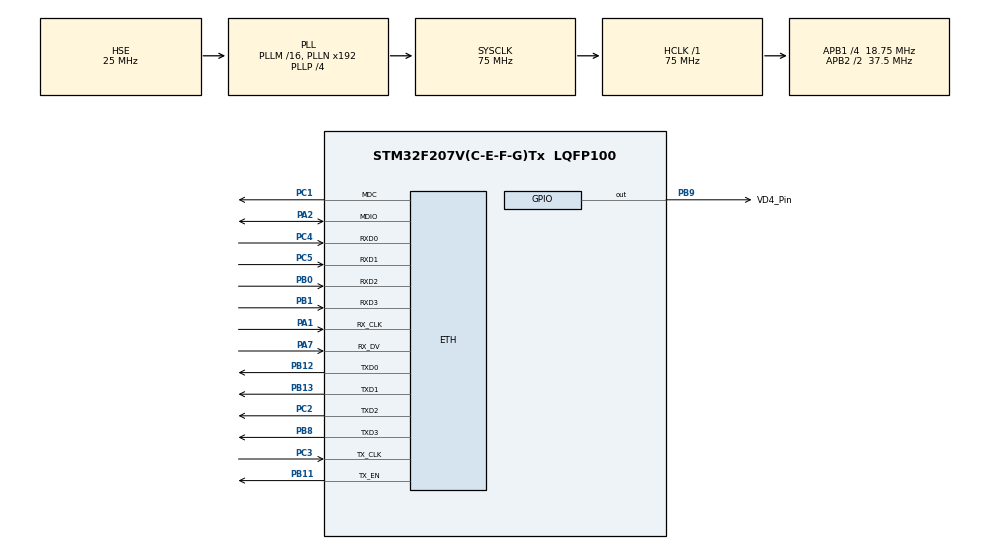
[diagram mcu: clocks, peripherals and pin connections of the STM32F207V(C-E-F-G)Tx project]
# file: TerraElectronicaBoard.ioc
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ETH.MediaInterface=ETH_MEDIA_INTERFACE_MII
ETH.PHY_Name_MII=userPHY
ETH.PHY_User_Name=RTL8201CP
ETH.PhyAddress=31
FREERTOS.Tasks01=defaultTask,0,128,StartDefaultTask,Default,NULL,Dynamic,NULL,NULL
LWIP.IP_ADDRESS=192.168.124.111
LWIP.LWIP_DHCP=0
LWIP.NETMASK_ADDRESS=255.255.255.000
LWIP.Version=v2.0.3_Cube
Mcu.Family=STM32F2
Mcu.Name=STM32F207V(C-E-F-G)Tx
Mcu.Package=LQFP100
NVIC.ETH_IRQn=true\:5\:0\:false\:false\:true\:true\:false\:true
NVIC.PriorityGroup=NVIC_PRIORITYGROUP_4
PA1.Mode=MII Full Duplex Only
PA1.Signal=ETH_RX_CLK
PA2.Mode=MII Full Duplex Only
PA2.Signal=ETH_MDIO
PA7.Mode=MII Full Duplex Only
PA7.Signal=ETH_RX_DV
PB0.Mode=MII Full Duplex Only
PB0.Signal=ETH_RXD2
PB1.Mode=MII Full Duplex Only
PB1.Signal=ETH_RXD3
PB11.Mode=MII Full Duplex Only
PB11.Signal=ETH_TX_EN
PB12.Mode=MII Full Duplex Only
PB12.Signal=ETH_TXD0
PB13.Mode=MII Full Duplex Only
PB13.Signal=ETH_TXD1
PB8.Mode=MII Full Duplex Only
PB8.Signal=ETH_TXD3
PB9.GPIO_Label=VD4_Pin
PB9.Signal=GPIO_Output
PC1.Mode=MII Full Duplex Only
PC1.Signal=ETH_MDC
PC2.Mode=MII Full Duplex Only
PC2.Signal=ETH_TXD2
PC3.Mode=MII Full Duplex Only
PC3.Signal=ETH_TX_CLK
PC4.Mode=MII Full Duplex Only
PC4.Signal=ETH_RXD0
PC5.Mode=MII Full Duplex Only
PC5.Signal=ETH_RXD1
PH0-OSC_IN.Mode=HSE-External-Oscillator
PH0-OSC_IN.Signal=RCC_OSC_IN
PH1-OSC_OUT.Mode=HSE-External-Oscillator
PH1-OSC_OUT.Signal=RCC_OSC_OUT
ProjectManager.HeapSize=0x200
ProjectManager.StackSize=0x400
ProjectManager.TargetToolchain=Makefile
RCC.48MHZClocksFreq_Value=75000000
RCC.AHBFreq_Value=75000000
RCC.APB1CLKDivider=RCC_HCLK_DIV4
RCC.APB1Freq_Value=18750000
RCC.APB1TimFreq_Value=37500000
RCC.APB2CLKDivider=RCC_HCLK_DIV2
RCC.APB2Freq_Value=37500000
RCC.APB2TimFreq_Value=75000000
RCC.CortexFreq_Value=75000000
RCC.HCLKFreq_Value=75000000
RCC.HSE_VALUE=25000000
RCC.HSI_VALUE=16000000
RCC.LSE_VALUE=32768
RCC.PLLP=RCC_PLLP_DIV4
RCC.PLLSourceVirtual=RCC_PLLSOURCE_HSE
RCC.SYSCLKFreq_VALUE=75000000
RCC.SYSCLKSource=RCC_SYSCLKSOURCE_PLLCLK
RCC.VCOOutputFreq_Value=300000000
VP_FREERTOS_VS_CMSIS_V1.Mode=CMSIS_V1
VP_LWIP_VS_Enabled.Mode=Enabled
board=custom

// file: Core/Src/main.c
/* USER CODE BEGIN Header */
/**
  ******************************************************************************
  * @file           : main.c
  * @brief          : Main program body
  ******************************************************************************
  * @attention
  *
  * <h2><center>&copy; Copyright (c) 2021 STMicroelectronics.
  * All rights reserved.</center></h2>
  *
  * This software component is licensed by ST under Ultimate Liberty license
  * SLA0044, the "License"; You may not use this file except in compliance with
  * the License. You may obtain a copy of the License at:
  *                             www.st.com/SLA0044
  *
  ******************************************************************************
  */
/* USER CODE END Header */
#include "main.h"
#include "cmsis_os.h"
#include "lwip.h"

osThreadId defaultTaskHandle;
/* USER CODE BEGIN PV */
osThreadId lwipTaskHandle;
/* USER CODE END PV */

void SystemClock_Config(void);
static void MX_GPIO_Init(void);
void StartDefaultTask(void const * argument);

/* USER CODE BEGIN PFP */
void StartLWIPTask(void const * argument);
/* USER CODE END PFP */

int main(void)
{

  /* MCU Configuration--------------------------------------------------------*/

  /* Reset of all peripherals, Initializes the Flash interface and the Systick. */
  HAL_Init();

  /* Configure the system clock */
  SystemClock_Config();

  /* Initialize all configured peripherals */
  MX_GPIO_Init();

  /* Create the thread(s) */
  /* definition and creation of defaultTask */
  osThreadDef(defaultTask, StartDefaultTask, osPriorityNormal, 0, 128);
  defaultTaskHandle = osThreadCreate(osThread(defaultTask), NULL);

  /* USER CODE BEGIN RTOS_THREADS */
  osThreadDef(lwipTask, StartLWIPTask, osPriorityNormal, 0, 512);
  lwipTaskHandle = osThreadCreate(osThread(lwipTask), NULL);
  /* USER CODE END RTOS_THREADS */

  /* Start scheduler */
  osKernelStart();

  /* We should never get here as control is now taken by the scheduler */
  /* Infinite loop */
  while (1)
  {

  }
}

void SystemClock_Config(void)
{
  RCC_OscInitTypeDef RCC_OscInitStruct = {0};
  RCC_ClkInitTypeDef RCC_ClkInitStruct = {0};

  /** Initializes the RCC Oscillators according to the specified parameters
  * in the RCC_OscInitTypeDef structure.
  */
  RCC_OscInitStruct.OscillatorType = RCC_OSCILLATORTYPE_HSE;
  RCC_OscInitStruct.HSEState = RCC_HSE_ON;
  RCC_OscInitStruct.PLL.PLLState = RCC_PLL_ON;
  RCC_OscInitStruct.PLL.PLLSource = RCC_PLLSOURCE_HSE;
  RCC_OscInitStruct.PLL.PLLM = 16;
  RCC_OscInitStruct.PLL.PLLN = 192;
  RCC_OscInitStruct.PLL.PLLP = RCC_PLLP_DIV4;
  RCC_OscInitStruct.PLL.PLLQ = 4;
  if (HAL_RCC_OscConfig(&RCC_OscInitStruct) != HAL_OK)
  {
    Error_Handler();
  }
  /** Initializes the CPU, AHB and APB buses clocks
  */
  RCC_ClkInitStruct.ClockType = RCC_CLOCKTYPE_HCLK|RCC_CLOCKTYPE_SYSCLK
                              |RCC_CLOCKTYPE_PCLK1|RCC_CLOCKTYPE_PCLK2;
  RCC_ClkInitStruct.SYSCLKSource = RCC_SYSCLKSOURCE_PLLCLK;
  RCC_ClkInitStruct.AHBCLKDivider = RCC_SYSCLK_DIV1;
  RCC_ClkInitStruct.APB1CLKDivider = RCC_HCLK_DIV4;
  RCC_ClkInitStruct.APB2CLKDivider = RCC_HCLK_DIV2;

  if (HAL_RCC_ClockConfig(&RCC_ClkInitStruct, FLASH_LATENCY_2) != HAL_OK)
  {
    Error_Handler();
  }
}

static void MX_GPIO_Init(void)
{
  GPIO_InitTypeDef GPIO_InitStruct = {0};

  /* GPIO Ports Clock Enable */
  __HAL_RCC_GPIOH_CLK_ENABLE();
  __HAL_RCC_GPIOC_CLK_ENABLE();
  __HAL_RCC_GPIOA_CLK_ENABLE();
  __HAL_RCC_GPIOB_CLK_ENABLE();

  /*Configure GPIO pin Output Level */
  HAL_GPIO_WritePin(VD4_Pin_GPIO_Port, VD4_Pin_Pin, GPIO_PIN_RESET);

  /*Configure GPIO pin : VD4_Pin_Pin */
  GPIO_InitStruct.Pin = VD4_Pin_Pin;
  GPIO_InitStruct.Mode = GPIO_MODE_OUTPUT_PP;
  GPIO_InitStruct.Pull = GPIO_NOPULL;
  GPIO_InitStruct.Speed = GPIO_SPEED_FREQ_LOW;
  HAL_GPIO_Init(VD4_Pin_GPIO_Port, &GPIO_InitStruct);

}

/* USER CODE BEGIN 4 */
/**
 * @brief Процесс обработки пакетов LWIP
 *
 * @param argument Аргументы запуска
 */
void StartLWIPTask(void const * argument) {
  MX_LWIP_Init();

  while (1)
  {
    /// Возможно, тут надо добавить функцию MX_LWIP_Process(), которой почему-то нет при сборке с RTOS
  }
}
/* USER CODE END 4 */

void StartDefaultTask(void const * argument)
{
  /* init code for LWIP */
  // MX_LWIP_Init();
  /* USER CODE BEGIN 5 */
  /* Infinite loop */
  for(;;)
  {
    osDelay(1000);
    if (initPHYStatus) {
      HAL_GPIO_WritePin(VD4_Pin_GPIO_Port, VD4_Pin_Pin, GPIO_PIN_SET);
    } else {
      HAL_GPIO_WritePin(VD4_Pin_GPIO_Port, VD4_Pin_Pin, GPIO_PIN_RESET);
    }
  }
  /* USER CODE END 5 */
}

void Error_Handler(void)
{
  __disable_irq();
  while (1)
  {
  }
}

/************************ (C) COPYRIGHT STMicroelectronics *****END OF FILE****/
